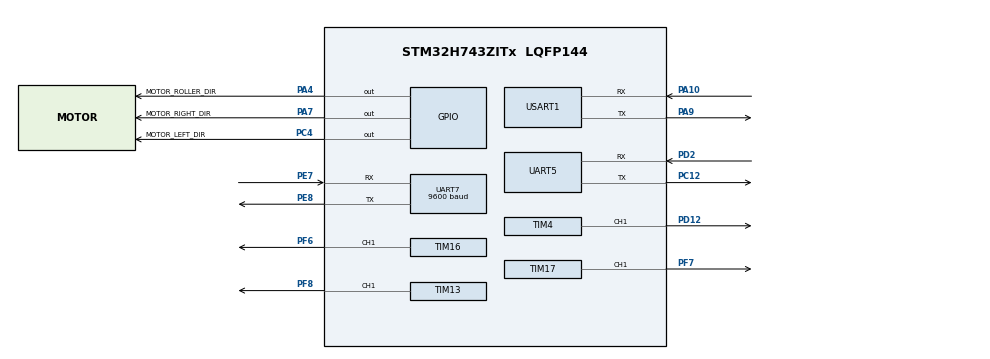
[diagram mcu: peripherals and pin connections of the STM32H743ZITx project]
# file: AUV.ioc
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CORTEX_M7.CPU_DCache=Enabled
CORTEX_M7.CPU_ICache=Enabled
CORTEX_M7.default_mode_Activation=1
FREERTOS.Tasks01=defaultTask,24,128,StartDefaultTask,Default,NULL,Dynamic,NULL,NULL
FREERTOS.configTOTAL_HEAP_SIZE=65536
Mcu.Family=STM32H7
Mcu.Name=STM32H743ZITx
Mcu.Package=LQFP144
NVIC.PriorityGroup=NVIC_PRIORITYGROUP_4
NVIC.TIM15_IRQn=true\:15\:0\:false\:false\:true\:false\:false\:true\:true
NVIC.TimeBase=TIM15_IRQn
NVIC.TimeBaseIP=TIM15
NVIC.UART5_IRQn=true\:5\:0\:false\:false\:true\:true\:true\:true\:true
NVIC.UART7_IRQn=true\:5\:0\:false\:false\:true\:false\:false\:true\:true
NVIC.USART1_IRQn=true\:5\:0\:false\:false\:true\:false\:false\:true\:true
PA10.Mode=Asynchronous
PA10.Signal=USART1_RX
PA13\ (JTMS/SWDIO).Mode=Serial_Wire
PA13\ (JTMS/SWDIO).Signal=DEBUG_JTMS-SWDIO
PA14\ (JTCK/SWCLK).Mode=Serial_Wire
PA14\ (JTCK/SWCLK).Signal=DEBUG_JTCK-SWCLK
PA4.GPIO_Label=MOTOR_ROLLER_DIR
PA4.Signal=GPIO_Output
PA7.GPIO_Label=MOTOR_RIGHT_DIR
PA7.Signal=GPIO_Output
PA9.Mode=Asynchronous
PA9.Signal=USART1_TX
PC12.Mode=Asynchronous
PC12.Signal=UART5_TX
PC4.GPIO_Label=MOTOR_LEFT_DIR
PC4.Signal=GPIO_Output
PD12.Signal=S_TIM4_CH1
PD2.Mode=Asynchronous
PD2.Signal=UART5_RX
PE7.Mode=Asynchronous
PE7.Signal=UART7_RX
PE8.Mode=Asynchronous
PE8.Signal=UART7_TX
PF6.Signal=S_TIM16_CH1
PF7.Signal=S_TIM17_CH1
PF8.Signal=S_TIM13_CH1
PH0-OSC_IN\ (PH0).Mode=HSE-External-Oscillator
PH0-OSC_IN\ (PH0).Signal=RCC_OSC_IN
PH1-OSC_OUT\ (PH1).Mode=HSE-External-Oscillator
PH1-OSC_OUT\ (PH1).Signal=RCC_OSC_OUT
ProjectManager.HeapSize=0x200
ProjectManager.StackSize=0x400
ProjectManager.TargetToolchain=MDK-ARM V5.32
RCC.ADCFreq_Value=50390625
RCC.APB1Freq_Value=100000000
RCC.APB2Freq_Value=100000000
RCC.APB3Freq_Value=100000000
RCC.APB4Freq_Value=100000000
RCC.CortexFreq_Value=400000000
RCC.D1PPRE=RCC_APB3_DIV2
RCC.D2PPRE1=RCC_APB1_DIV2
RCC.D2PPRE2=RCC_APB2_DIV2
RCC.D3PPRE=RCC_APB4_DIV2
RCC.DIVM1=2
RCC.DIVN1=64
RCC.HCLKFreq_Value=200000000
RCC.HPRE=RCC_HCLK_DIV2
RCC.PLL2FRACN=0
RCC.PLL3FRACN=0
RCC.PLLFRACN=0
RCC.PLLSourceVirtual=RCC_PLLSOURCE_HSE
RCC.SYSCLKFreq_VALUE=400000000
RCC.SYSCLKSource=RCC_SYSCLKSOURCE_PLLCLK
RCC.USBFreq_Value=400000000
SH.S_TIM13_CH1.0=TIM13_CH1,PWM Generation1 CH1
SH.S_TIM16_CH1.0=TIM16_CH1,PWM Generation1 CH1
SH.S_TIM17_CH1.0=TIM17_CH1,PWM Generation1 CH1
SH.S_TIM4_CH1.0=TIM4_CH1,PWM Generation1 CH1
TIM13.Channel=TIM_CHANNEL_1
TIM13.OCPolarity_1=TIM_OCPOLARITY_LOW
TIM13.Period=99
TIM13.Prescaler=63
TIM16.Channel=TIM_CHANNEL_1
TIM16.OCPolarity_1=TIM_OCPOLARITY_LOW
TIM16.Period=99
TIM16.Prescaler=63
TIM17.Channel=TIM_CHANNEL_1
TIM17.OCPolarity_1=TIM_OCPOLARITY_LOW
TIM17.Period=99
TIM17.Prescaler=63
TIM4.Channel-PWM\ Generation1\ CH1=TIM_CHANNEL_1
TIM4.Period=19999
TIM4.Prescaler=199
UART7.BaudRate=9600
USART1.VirtualMode-Asynchronous=VM_ASYNC
VP_FREERTOS_VS_CMSIS_V2.Mode=CMSIS_V2
VP_MEMORYMAP_VS_MEMORYMAP.Mode=CurAppReg
VP_SYS_VS_tim15.Mode=TIM15
VP_TIM13_VS_ClockSourceINT.Mode=Enable_Timer
VP_TIM16_VS_ClockSourceINT.Mode=Enable_Timer
VP_TIM17_VS_ClockSourceINT.Mode=Enable_Timer
board=custom

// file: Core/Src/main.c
/* USER CODE BEGIN Header */
/**
  ******************************************************************************
  * @file           : main.c
  * @brief          : Main program body
  ******************************************************************************
  * @attention
  *
  * Copyright (c) 2026 STMicroelectronics.
  * All rights reserved.
  *
  * This software is licensed under terms that can be found in the LICENSE file
  * in the root directory of this software component.
  * If no LICENSE file comes with this software, it is provided AS-IS.
  *
  ******************************************************************************
  */
/* USER CODE END Header */
#include "main.h"
#include "FreeRTOS.h"
#include "cmsis_os2.h"

/* USER CODE BEGIN Includes */
#include "app_task_init.h"
#include "jy901s.h"
#include "motor.h"

/* USER CODE END Includes */

TIM_HandleTypeDef htim4;
TIM_HandleTypeDef htim13;
TIM_HandleTypeDef htim16;
TIM_HandleTypeDef htim17;

UART_HandleTypeDef huart5;
UART_HandleTypeDef huart7;
UART_HandleTypeDef huart1;

/* Definitions for defaultTask */
osThreadId_t defaultTaskHandle;
const osThreadAttr_t defaultTask_attributes = {
  .name = "defaultTask",
  .stack_size = 128 * 4,
  .priority = (osPriority_t) osPriorityNormal,
};

void SystemClock_Config(void);
static void MPU_Config(void);
static void MX_GPIO_Init(void);
static void MX_USART1_UART_Init(void);
static void MX_TIM4_Init(void);
static void MX_TIM13_Init(void);
static void MX_TIM16_Init(void);
static void MX_TIM17_Init(void);
static void MX_UART7_Init(void);
static void MX_UART5_Init(void);
void StartDefaultTask(void *argument);

int main(void)
{

  /* MPU Configuration--------------------------------------------------------*/
  MPU_Config();

  /* Enable the CPU Cache */

  /* Enable I-Cache---------------------------------------------------------*/
  SCB_EnableICache();

  /* Enable D-Cache---------------------------------------------------------*/
  SCB_EnableDCache();

  /* MCU Configuration--------------------------------------------------------*/

  /* Reset of all peripherals, Initializes the Flash interface and the Systick. */
  HAL_Init();

  /* Configure the system clock */
  SystemClock_Config();

  /* Initialize all configured peripherals */
  MX_GPIO_Init();
  MX_USART1_UART_Init();
  MX_TIM4_Init();
  MX_TIM13_Init();
  MX_TIM16_Init();
  MX_TIM17_Init();
  MX_UART7_Init();
  MX_UART5_Init();
  /* USER CODE BEGIN 2 */
  if (Motor_Init() != HAL_OK)
  {
    Error_Handler();
  }

  /* USER CODE END 2 */

  /* Init scheduler */
  osKernelInitialize();

  /* Create the thread(s) */
  /* creation of defaultTask */
  defaultTaskHandle = osThreadNew(StartDefaultTask, NULL, &defaultTask_attributes);

  /* USER CODE BEGIN RTOS_THREADS */
  /* add threads, ... */
  App_Task_Init();
  /* USER CODE END RTOS_THREADS */

  /* Start scheduler */
  osKernelStart();

  /* We should never get here as control is now taken by the scheduler */

  /* Infinite loop */
  while (1)
  {

  }
}

void SystemClock_Config(void)
{
  RCC_OscInitTypeDef RCC_OscInitStruct = {0};
  RCC_ClkInitTypeDef RCC_ClkInitStruct = {0};

  /** Supply configuration update enable
  */
  HAL_PWREx_ConfigSupply(PWR_LDO_SUPPLY);

  /** Configure the main internal regulator output voltage
  */
  __HAL_PWR_VOLTAGESCALING_CONFIG(PWR_REGULATOR_VOLTAGE_SCALE1);

  while(!__HAL_PWR_GET_FLAG(PWR_FLAG_VOSRDY)) {}

  /** Initializes the RCC Oscillators according to the specified parameters
  * in the RCC_OscInitTypeDef structure.
  */
  RCC_OscInitStruct.OscillatorType = RCC_OSCILLATORTYPE_HSE;
  RCC_OscInitStruct.HSEState = RCC_HSE_ON;
  RCC_OscInitStruct.PLL.PLLState = RCC_PLL_ON;
  RCC_OscInitStruct.PLL.PLLSource = RCC_PLLSOURCE_HSE;
  RCC_OscInitStruct.PLL.PLLM = 2;
  RCC_OscInitStruct.PLL.PLLN = 64;
  RCC_OscInitStruct.PLL.PLLP = 2;
  RCC_OscInitStruct.PLL.PLLQ = 2;
  RCC_OscInitStruct.PLL.PLLR = 2;
  RCC_OscInitStruct.PLL.PLLRGE = RCC_PLL1VCIRANGE_3;
  RCC_OscInitStruct.PLL.PLLVCOSEL = RCC_PLL1VCOWIDE;
  RCC_OscInitStruct.PLL.PLLFRACN = 0;
  if (HAL_RCC_OscConfig(&RCC_OscInitStruct) != HAL_OK)
  {
    Error_Handler();
  }

  /** Initializes the CPU, AHB and APB buses clocks
  */
  RCC_ClkInitStruct.ClockType = RCC_CLOCKTYPE_HCLK|RCC_CLOCKTYPE_SYSCLK
                              |RCC_CLOCKTYPE_PCLK1|RCC_CLOCKTYPE_PCLK2
                              |RCC_CLOCKTYPE_D3PCLK1|RCC_CLOCKTYPE_D1PCLK1;
  RCC_ClkInitStruct.SYSCLKSource = RCC_SYSCLKSOURCE_PLLCLK;
  RCC_ClkInitStruct.SYSCLKDivider = RCC_SYSCLK_DIV1;
  RCC_ClkInitStruct.AHBCLKDivider = RCC_HCLK_DIV2;
  RCC_ClkInitStruct.APB3CLKDivider = RCC_APB3_DIV2;
  RCC_ClkInitStruct.APB1CLKDivider = RCC_APB1_DIV2;
  RCC_ClkInitStruct.APB2CLKDivider = RCC_APB2_DIV2;
  RCC_ClkInitStruct.APB4CLKDivider = RCC_APB4_DIV2;

  if (HAL_RCC_ClockConfig(&RCC_ClkInitStruct, FLASH_LATENCY_2) != HAL_OK)
  {
    Error_Handler();
  }
}

static void MX_TIM4_Init(void)
{

  TIM_MasterConfigTypeDef sMasterConfig = {0};
  TIM_OC_InitTypeDef sConfigOC = {0};

  htim4.Instance = TIM4;
  htim4.Init.Prescaler = 199;
  htim4.Init.CounterMode = TIM_COUNTERMODE_UP;
  htim4.Init.Period = 19999;
  htim4.Init.ClockDivision = TIM_CLOCKDIVISION_DIV1;
  htim4.Init.AutoReloadPreload = TIM_AUTORELOAD_PRELOAD_DISABLE;
  if (HAL_TIM_PWM_Init(&htim4) != HAL_OK)
  {
    Error_Handler();
  }
  sMasterConfig.MasterOutputTrigger = TIM_TRGO_RESET;
  sMasterConfig.MasterSlaveMode = TIM_MASTERSLAVEMODE_DISABLE;
  if (HAL_TIMEx_MasterConfigSynchronization(&htim4, &sMasterConfig) != HAL_OK)
  {
    Error_Handler();
  }
  sConfigOC.OCMode = TIM_OCMODE_PWM1;
  sConfigOC.Pulse = 0;
  sConfigOC.OCPolarity = TIM_OCPOLARITY_HIGH;
  sConfigOC.OCFastMode = TIM_OCFAST_DISABLE;
  if (HAL_TIM_PWM_ConfigChannel(&htim4, &sConfigOC, TIM_CHANNEL_1) != HAL_OK)
  {
    Error_Handler();
  }
  HAL_TIM_MspPostInit(&htim4);

}

static void MX_TIM13_Init(void)
{

  TIM_OC_InitTypeDef sConfigOC = {0};

  htim13.Instance = TIM13;
  htim13.Init.Prescaler = 63;
  htim13.Init.CounterMode = TIM_COUNTERMODE_UP;
  htim13.Init.Period = 99;
  htim13.Init.ClockDivision = TIM_CLOCKDIVISION_DIV1;
  htim13.Init.AutoReloadPreload = TIM_AUTORELOAD_PRELOAD_DISABLE;
  if (HAL_TIM_Base_Init(&htim13) != HAL_OK)
  {
    Error_Handler();
  }
  if (HAL_TIM_PWM_Init(&htim13) != HAL_OK)
  {
    Error_Handler();
  }
  sConfigOC.OCMode = TIM_OCMODE_PWM1;
  sConfigOC.Pulse = 0;
  sConfigOC.OCPolarity = TIM_OCPOLARITY_LOW;
  sConfigOC.OCFastMode = TIM_OCFAST_DISABLE;
  if (HAL_TIM_PWM_ConfigChannel(&htim13, &sConfigOC, TIM_CHANNEL_1) != HAL_OK)
  {
    Error_Handler();
  }
  HAL_TIM_MspPostInit(&htim13);

}

static void MX_TIM16_Init(void)
{

  TIM_OC_InitTypeDef sConfigOC = {0};
  TIM_BreakDeadTimeConfigTypeDef sBreakDeadTimeConfig = {0};

  htim16.Instance = TIM16;
  htim16.Init.Prescaler = 63;
  htim16.Init.CounterMode = TIM_COUNTERMODE_UP;
  htim16.Init.Period = 99;
  htim16.Init.ClockDivision = TIM_CLOCKDIVISION_DIV1;
  htim16.Init.RepetitionCounter = 0;
  htim16.Init.AutoReloadPreload = TIM_AUTORELOAD_PRELOAD_DISABLE;
  if (HAL_TIM_Base_Init(&htim16) != HAL_OK)
  {
    Error_Handler();
  }
  if (HAL_TIM_PWM_Init(&htim16) != HAL_OK)
  {
    Error_Handler();
  }
  sConfigOC.OCMode = TIM_OCMODE_PWM1;
  sConfigOC.Pulse = 0;
  sConfigOC.OCPolarity = TIM_OCPOLARITY_LOW;
  sConfigOC.OCNPolarity = TIM_OCNPOLARITY_HIGH;
  sConfigOC.OCFastMode = TIM_OCFAST_DISABLE;
  sConfigOC.OCIdleState = TIM_OCIDLESTATE_RESET;
  sConfigOC.OCNIdleState = TIM_OCNIDLESTATE_RESET;
  if (HAL_TIM_PWM_ConfigChannel(&htim16, &sConfigOC, TIM_CHANNEL_1) != HAL_OK)
  {
    Error_Handler();
  }
  sBreakDeadTimeConfig.OffStateRunMode = TIM_OSSR_DISABLE;
  sBreakDeadTimeConfig.OffStateIDLEMode = TIM_OSSI_DISABLE;
  sBreakDeadTimeConfig.LockLevel = TIM_LOCKLEVEL_OFF;
  sBreakDeadTimeConfig.DeadTime = 0;
  sBreakDeadTimeConfig.BreakState = TIM_BREAK_DISABLE;
  sBreakDeadTimeConfig.BreakPolarity = TIM_BREAKPOLARITY_HIGH;
  sBreakDeadTimeConfig.BreakFilter = 0;
  sBreakDeadTimeConfig.AutomaticOutput = TIM_AUTOMATICOUTPUT_DISABLE;
  if (HAL_TIMEx_ConfigBreakDeadTime(&htim16, &sBreakDeadTimeConfig) != HAL_OK)
  {
    Error_Handler();
  }
  HAL_TIM_MspPostInit(&htim16);

}

static void MX_TIM17_Init(void)
{

  TIM_OC_InitTypeDef sConfigOC = {0};
  TIM_BreakDeadTimeConfigTypeDef sBreakDeadTimeConfig = {0};

  htim17.Instance = TIM17;
  htim17.Init.Prescaler = 63;
  htim17.Init.CounterMode = TIM_COUNTERMODE_UP;
  htim17.Init.Period = 99;
  htim17.Init.ClockDivision = TIM_CLOCKDIVISION_DIV1;
  htim17.Init.RepetitionCounter = 0;
  htim17.Init.AutoReloadPreload = TIM_AUTORELOAD_PRELOAD_DISABLE;
  if (HAL_TIM_Base_Init(&htim17) != HAL_OK)
  {
    Error_Handler();
  }
  if (HAL_TIM_PWM_Init(&htim17) != HAL_OK)
  {
    Error_Handler();
  }
  sConfigOC.OCMode = TIM_OCMODE_PWM1;
  sConfigOC.Pulse = 0;
  sConfigOC.OCPolarity = TIM_OCPOLARITY_LOW;
  sConfigOC.OCNPolarity = TIM_OCNPOLARITY_HIGH;
  sConfigOC.OCFastMode = TIM_OCFAST_DISABLE;
  sConfigOC.OCIdleState = TIM_OCIDLESTATE_RESET;
  sConfigOC.OCNIdleState = TIM_OCNIDLESTATE_RESET;
  if (HAL_TIM_PWM_ConfigChannel(&htim17, &sConfigOC, TIM_CHANNEL_1) != HAL_OK)
  {
    Error_Handler();
  }
  sBreakDeadTimeConfig.OffStateRunMode = TIM_OSSR_DISABLE;
  sBreakDeadTimeConfig.OffStateIDLEMode = TIM_OSSI_DISABLE;
  sBreakDeadTimeConfig.LockLevel = TIM_LOCKLEVEL_OFF;
  sBreakDeadTimeConfig.DeadTime = 0;
  sBreakDeadTimeConfig.BreakState = TIM_BREAK_DISABLE;
  sBreakDeadTimeConfig.BreakPolarity = TIM_BREAKPOLARITY_HIGH;
  sBreakDeadTimeConfig.BreakFilter = 0;
  sBreakDeadTimeConfig.AutomaticOutput = TIM_AUTOMATICOUTPUT_DISABLE;
  if (HAL_TIMEx_ConfigBreakDeadTime(&htim17, &sBreakDeadTimeConfig) != HAL_OK)
  {
    Error_Handler();
  }
  HAL_TIM_MspPostInit(&htim17);

}

static void MX_UART5_Init(void)
{

  huart5.Instance = UART5;
  huart5.Init.BaudRate = 115200;
  huart5.Init.WordLength = UART_WORDLENGTH_8B;
  huart5.Init.StopBits = UART_STOPBITS_1;
  huart5.Init.Parity = UART_PARITY_NONE;
  huart5.Init.Mode = UART_MODE_TX_RX;
  huart5.Init.HwFlowCtl = UART_HWCONTROL_NONE;
  huart5.Init.OverSampling = UART_OVERSAMPLING_16;
  huart5.Init.OneBitSampling = UART_ONE_BIT_SAMPLE_DISABLE;
  huart5.Init.ClockPrescaler = UART_PRESCALER_DIV1;
  huart5.AdvancedInit.AdvFeatureInit = UART_ADVFEATURE_NO_INIT;
  if (HAL_UART_Init(&huart5) != HAL_OK)
  {
    Error_Handler();
  }
  if (HAL_UARTEx_SetTxFifoThreshold(&huart5, UART_TXFIFO_THRESHOLD_1_8) != HAL_OK)
  {
    Error_Handler();
  }
  if (HAL_UARTEx_SetRxFifoThreshold(&huart5, UART_RXFIFO_THRESHOLD_1_8) != HAL_OK)
  {
    Error_Handler();
  }
  if (HAL_UARTEx_DisableFifoMode(&huart5) != HAL_OK)
  {
    Error_Handler();
  }

}

static void MX_UART7_Init(void)
{

  huart7.Instance = UART7;
  huart7.Init.BaudRate = 9600;
  huart7.Init.WordLength = UART_WORDLENGTH_8B;
  huart7.Init.StopBits = UART_STOPBITS_1;
  huart7.Init.Parity = UART_PARITY_NONE;
  huart7.Init.Mode = UART_MODE_TX_RX;
  huart7.Init.HwFlowCtl = UART_HWCONTROL_NONE;
  huart7.Init.OverSampling = UART_OVERSAMPLING_16;
  huart7.Init.OneBitSampling = UART_ONE_BIT_SAMPLE_DISABLE;
  huart7.Init.ClockPrescaler = UART_PRESCALER_DIV1;
  huart7.AdvancedInit.AdvFeatureInit = UART_ADVFEATURE_NO_INIT;
  if (HAL_UART_Init(&huart7) != HAL_OK)
  {
    Error_Handler();
  }
  if (HAL_UARTEx_SetTxFifoThreshold(&huart7, UART_TXFIFO_THRESHOLD_1_8) != HAL_OK)
  {
    Error_Handler();
  }
  if (HAL_UARTEx_SetRxFifoThreshold(&huart7, UART_RXFIFO_THRESHOLD_1_8) != HAL_OK)
  {
    Error_Handler();
  }
  if (HAL_UARTEx_DisableFifoMode(&huart7) != HAL_OK)
  {
    Error_Handler();
  }

}

static void MX_USART1_UART_Init(void)
{

  huart1.Instance = USART1;
  huart1.Init.BaudRate = 115200;
  huart1.Init.WordLength = UART_WORDLENGTH_8B;
  huart1.Init.StopBits = UART_STOPBITS_1;
  huart1.Init.Parity = UART_PARITY_NONE;
  huart1.Init.Mode = UART_MODE_TX_RX;
  huart1.Init.HwFlowCtl = UART_HWCONTROL_NONE;
  huart1.Init.OverSampling = UART_OVERSAMPLING_16;
  huart1.Init.OneBitSampling = UART_ONE_BIT_SAMPLE_DISABLE;
  huart1.Init.ClockPrescaler = UART_PRESCALER_DIV1;
  huart1.AdvancedInit.AdvFeatureInit = UART_ADVFEATURE_NO_INIT;
  if (HAL_UART_Init(&huart1) != HAL_OK)
  {
    Error_Handler();
  }
  if (HAL_UARTEx_SetTxFifoThreshold(&huart1, UART_TXFIFO_THRESHOLD_1_8) != HAL_OK)
  {
    Error_Handler();
  }
  if (HAL_UARTEx_SetRxFifoThreshold(&huart1, UART_RXFIFO_THRESHOLD_1_8) != HAL_OK)
  {
    Error_Handler();
  }
  if (HAL_UARTEx_DisableFifoMode(&huart1) != HAL_OK)
  {
    Error_Handler();
  }

}

static void MX_GPIO_Init(void)
{
  GPIO_InitTypeDef GPIO_InitStruct = {0};

  /* GPIO Ports Clock Enable */
  __HAL_RCC_GPIOF_CLK_ENABLE();
  __HAL_RCC_GPIOH_CLK_ENABLE();
  __HAL_RCC_GPIOA_CLK_ENABLE();
  __HAL_RCC_GPIOC_CLK_ENABLE();
  __HAL_RCC_GPIOE_CLK_ENABLE();
  __HAL_RCC_GPIOD_CLK_ENABLE();

  /*Configure GPIO pin Output Level */
  HAL_GPIO_WritePin(GPIOA, MOTOR_ROLLER_DIR_Pin|MOTOR_RIGHT_DIR_Pin, GPIO_PIN_RESET);

  /*Configure GPIO pin Output Level */
  HAL_GPIO_WritePin(MOTOR_LEFT_DIR_GPIO_Port, MOTOR_LEFT_DIR_Pin, GPIO_PIN_RESET);

  /*Configure GPIO pins : MOTOR_ROLLER_DIR_Pin MOTOR_RIGHT_DIR_Pin */
  GPIO_InitStruct.Pin = MOTOR_ROLLER_DIR_Pin|MOTOR_RIGHT_DIR_Pin;
  GPIO_InitStruct.Mode = GPIO_MODE_OUTPUT_PP;
  GPIO_InitStruct.Pull = GPIO_NOPULL;
  GPIO_InitStruct.Speed = GPIO_SPEED_FREQ_LOW;
  HAL_GPIO_Init(GPIOA, &GPIO_InitStruct);

  /*Configure GPIO pin : MOTOR_LEFT_DIR_Pin */
  GPIO_InitStruct.Pin = MOTOR_LEFT_DIR_Pin;
  GPIO_InitStruct.Mode = GPIO_MODE_OUTPUT_PP;
  GPIO_InitStruct.Pull = GPIO_NOPULL;
  GPIO_InitStruct.Speed = GPIO_SPEED_FREQ_LOW;
  HAL_GPIO_Init(MOTOR_LEFT_DIR_GPIO_Port, &GPIO_InitStruct);

}

void StartDefaultTask(void *argument)
{
  for(;;)
  {
    osDelay(1);
  }
}

 /* MPU Configuration */

void MPU_Config(void)
{
  MPU_Region_InitTypeDef MPU_InitStruct = {0};

  /* Disables the MPU */
  HAL_MPU_Disable();

  /** Initializes and configures the Region and the memory to be protected
  */
  MPU_InitStruct.Enable = MPU_REGION_ENABLE;
  MPU_InitStruct.Number = MPU_REGION_NUMBER0;
  MPU_InitStruct.BaseAddress = 0x0;
  MPU_InitStruct.Size = MPU_REGION_SIZE_4GB;
  MPU_InitStruct.SubRegionDisable = 0x87;
  MPU_InitStruct.TypeExtField = MPU_TEX_LEVEL0;
  MPU_InitStruct.AccessPermission = MPU_REGION_NO_ACCESS;
  MPU_InitStruct.DisableExec = MPU_INSTRUCTION_ACCESS_DISABLE;
  MPU_InitStruct.IsShareable = MPU_ACCESS_SHAREABLE;
  MPU_InitStruct.IsCacheable = MPU_ACCESS_NOT_CACHEABLE;
  MPU_InitStruct.IsBufferable = MPU_ACCESS_NOT_BUFFERABLE;

  HAL_MPU_ConfigRegion(&MPU_InitStruct);
  /* Enables the MPU */
  HAL_MPU_Enable(MPU_PRIVILEGED_DEFAULT);

}

void HAL_TIM_PeriodElapsedCallback(TIM_HandleTypeDef *htim)
{
  if (htim->Instance == TIM15)
  {
    HAL_IncTick();
  }
}

void Error_Handler(void)
{
  __disable_irq();
  while (1)
  {
  }
}
